# STM32H523 register map
File version: 1.3
CPU: CM33 r0p0, little endian, MPU, FPU, 4 interrupt priority bits
Registers are 32-bit, read-write, reset 0x0 unless marked. A register's access mark holds for its fields unless they carry their own. Offsets are from the block's base; [hi:lo] are bit positions.

## USART1 — USART address block description
Base 0x40013800
Same registers: USART2 0x40004400, USART3 0x40004800, UART4 0x40004C00, UART5 0x40005000, USART6 0x40006400, USART2_S 0x50004400, USART3_S 0x50004800, UART4_S 0x50004C00, UART5_S 0x50005000, USART6_S 0x50006400, USART1_S 0x50013800
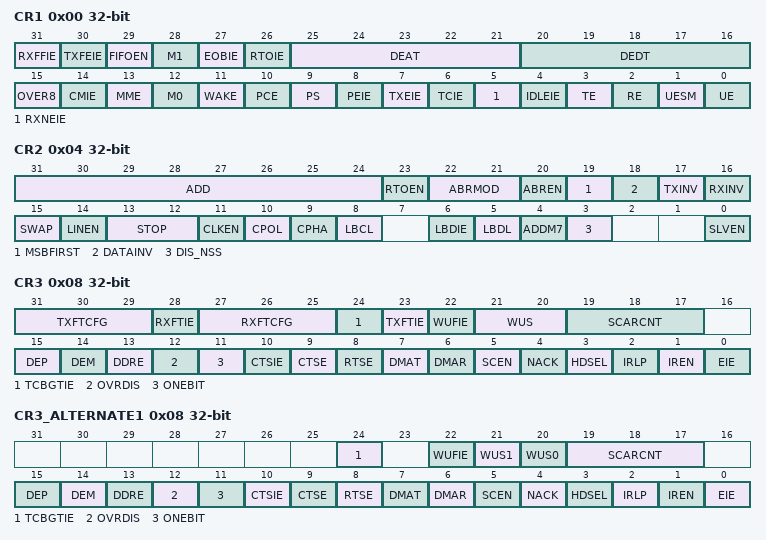
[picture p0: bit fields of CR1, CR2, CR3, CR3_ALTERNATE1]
0x00 CR1 — USART control register 1
  [31] RXFFIE — RXFIFO Full interrupt enable
    0=Disabled (Interrupt inhibited); 1=Enabled (USART interrupt generated when RXFF = 1 in the USART_ISR register)
  [30] TXFEIE — TXFIFO empty interrupt enable
    0=Disabled (Interrupt inhibited); 1=Enabled (USART interrupt generated when TXFE = 1 in the USART_ISR register)
  [29] FIFOEN — FIFO mode enable
    0=Disabled (FIFO mode is disabled); 1=Enabled (FIFO mode is enabled)
  [28] M1 — Word length
    0=M0 (Use M0 to set the data bits); 1=Bit7 (1 start bit, 7 data bits, n stop bits)
  [27] EOBIE — End of block interrupt enable
    0=Disabled (Interrupt is inhibited); 1=Enabled (A USART interrupt is generated when the EOBF flag is set in the ISR register)
  [26] RTOIE — Receiver timeout interrupt enable
    0=Disabled (Interrupt is inhibited); 1=Enabled (An USART interrupt is generated when the RTOF bit is set in the ISR register)
  [25:21] DEAT — Driver Enable assertion time
  [20:16] DEDT — Driver Enable deassertion time
  [15] OVER8 — Oversampling mode
    0=Oversampling16 (Oversampling by 16); 1=Oversampling8 (Oversampling by 8)
  [14] CMIE — Character match interrupt enable
    0=Disabled (Interrupt is disabled); 1=Enabled (Interrupt is generated when the CMF bit is set in the ISR register)
  [13] MME — Mute mode enable
    0=Disabled (Receiver in active mode permanently); 1=Enabled (Receiver can switch between mute mode and active mode)
  [12] M0 — Word length
    0=Bit8 (1 start bit, 8 data bits, n stop bits); 1=Bit9 (1 start bit, 9 data bits, n stop bits)
  [11] WAKE — Receiver wake-up method
    0=Idle line; 1=Address mask
  [10] PCE — Parity control enable
    0=Disabled (Parity control disabled); 1=Enabled (Parity control enabled)
  [9] PS — Parity selection
    0=Even parity; 1=Odd (Odd parity)
  [8] PEIE — PE interrupt enable
    0=Disabled (Interrupt is disabled); 1=Enabled (Interrupt is generated whenever PE=1 in the ISR register)
  [7] TXEIE — TXFIFO not full interrupt enable
    0=Disabled (Interrupt is disabled); 1=Enabled (Interrupt is generated whenever TXE=1 in the ISR register)
  [6] TCIE — Transmission complete interrupt enable
    0=Disabled (Interrupt is disabled); 1=Enabled (Interrupt is generated whenever TC=1 in the ISR register)
  [5] RXNEIE — RXFIFO not empty interrupt enable
    0=Disabled (Interrupt is disabled); 1=Enabled (Interrupt is generated whenever ORE=1 or RXNE=1 in the ISR register)
  [4] IDLEIE — IDLE interrupt enable
    0=Disabled (Interrupt is disabled); 1=Enabled (Interrupt is generated whenever IDLE=1 in the ISR register)
  [3] TE — Transmitter enable
    0=Disabled (Transmitter is disabled); 1=Enabled (Transmitter is enabled)
  [2] RE — Receiver enable
    0=Disabled (Receiver is disabled); 1=Enabled (Receiver is enabled)
  [1] UESM — USART enable in low-power mode
    0=Disabled (USART not able to wake up the MCU from Stop mode); 1=Enabled (USART able to wake up the MCU from Stop mode)
  [0] UE — USART enable
    0=Disabled (UART is disabled); 1=Enabled (UART is enabled)
0x04 CR2 — USART control register 2
  [31:24] ADD — Address of the USART node
  [23] RTOEN — Receiver timeout enable
    0=Disabled (Receiver timeout feature disabled); 1=Enabled (Receiver timeout feature enabled)
  [22:21] ABRMOD — Auto baud rate mode
    0=Start (Measurement of the start bit is used to detect the baud rate); 1=Edge (Falling edge to falling edge measurement); 2=Frame7F (0x7F frame detection); 3=Frame55 (0x55 frame detection)
  [20] ABREN — Auto baud rate enable
    0=Disabled (Auto baud rate detection is disabled); 1=Enabled (Auto baud rate detection is enabled)
  [19] MSBFIRST — Most significant bit first
    0=LSB (data is transmitted/received with data bit 0 first, following the start bit); 1=MSB (data is transmitted/received with MSB (bit 7/8/9) first, following the start bit)
  [18] DATAINV — Binary data inversion
    0=Positive (Logical data from the data register are send/received in positive/direct logic); 1=Negative (Logical data from the data register are send/received in negative/inverse logic)
  [17] TXINV — TX pin active level inversion
    0=Standard (TX pin signal works using the standard logic levels); 1=Inverted (TX pin signal values are inverted)
  [16] RXINV — RX pin active level inversion
    0=Standard (RX pin signal works using the standard logic levels); 1=Inverted (RX pin signal values are inverted)
  [15] SWAP — Swap TX/RX pins
    0=Standard (TX/RX pins are used as defined in standard pinout); 1=Swapped (The TX and RX pins functions are swapped)
  [14] LINEN — LIN mode enable
    0=Disabled (LIN mode disabled); 1=Enabled (LIN mode enabled)
  [13:12] STOP — stop bits
    0=1 stop bit; 1=Stop0p5 (0.5 stop bit); 2=2 stop bit; 3=Stop1p5 (1.5 stop bit)
  [11] CLKEN — Clock enable
    0=Disabled (CK pin disabled); 1=Enabled (CK pin enabled)
  [10] CPOL — Clock polarity
    0=Low (Steady low value on CK pin outside transmission window); 1=High (Steady high value on CK pin outside transmission window)
  [9] CPHA — Clock phase
    0=First (The first clock transition is the first data capture edge); 1=Second (The second clock transition is the first data capture edge)
  [8] LBCL — Last bit clock pulse
    0=NotOutput (The clock pulse of the last data bit is not output to the CK pin); 1=Output (The clock pulse of the last data bit is output to the CK pin)
  [6] LBDIE — LIN break detection interrupt enable
    0=Disabled (Interrupt is inhibited); 1=Enabled (An interrupt is generated whenever LBDF=1 in the ISR register)
  [5] LBDL — LIN break detection length
    0=Bit10 (10-bit break detection); 1=Bit11 (11-bit break detection)
  [4] ADDM7 — 7-bit Address Detection/4-bit Address Detection
    0=Bit4 (4-bit address detection); 1=Bit7 (7-bit address detection)
  [3] DIS_NSS — When the DIS_NSS bit is set, the NSS pin input is ignored.
    0=Disabled (SPI slave selection depends on NSS input pin); 1=Enabled (SPI slave is always selected and NSS input pin is ignored)
  [0] SLVEN — Synchronous slave mode enable
    0=Disabled (Slave mode disabled); 1=Enabled (Slave mode enabled)
0x08 CR3 — USART control register 3
  [31:29] TXFTCFG — TXFIFO threshold configuration
    0=Depth_1_8 (TXFIFO reaches 1/8 of its depth); 1=Depth_1_4 (TXFIFO reaches 1/4 of its depth); 2=Depth_1_2 (TXFIFO reaches 1/2 of its depth); 3=Depth_3_4 (TXFIFO reaches 3/4 of its depth); 4=Depth_7_8 (TXFIFO reaches 7/8 of its depth); 5=Empty (TXFIFO becomes empty)
  [28] RXFTIE — RXFIFO threshold interrupt enable
    0=Disabled (Interrupt inhibited); 1=Enabled (USART interrupt generated when Receive FIFO reaches the threshold programmed in RXFTCFG)
  [27:25] RXFTCFG — Receive FIFO threshold configuration
    0=Depth_1_8 (RXFIFO reaches 1/8 of its depth); 1=Depth_1_4 (RXFIFO reaches 1/4 of its depth); 2=Depth_1_2 (RXFIFO reaches 1/2 of its depth); 3=Depth_3_4 (RXFIFO reaches 3/4 of its depth); 4=Depth_7_8 (RXFIFO reaches 7/8 of its depth); 5=Full (RXFIFO becomes full)
  [24] TCBGTIE — Transmission Complete before guard time, interrupt enable
    0=Disabled (Interrupt inhibited); 1=Enabled (USART interrupt generated whenever TCBGT=1 in the USART_ISR register)
  [23] TXFTIE — TXFIFO threshold interrupt enable
    0=Disabled (Interrupt inhibited); 1=Enabled (USART interrupt generated when Transmit FIFO reaches the threshold programmed in TXFTCFG)
  [22] WUFIE — Wake-up from low-power mode interrupt enable
    0=Disabled (Interrupt is inhibited); 1=Enabled (An USART interrupt is generated whenever WUF=1 in the ISR register)
  [21:20] WUS — Wake-up from low-power mode interrupt flag selection
    0=Address (WUF active on address match); 2=Start (WuF active on Start bit detection); 3=RXNE (WUF active on RXNE)
  [19:17] SCARCNT — Smartcard auto-retry count
  [15] DEP — Driver enable polarity selection
    0=High (DE signal is active high); 1=Low (DE signal is active low)
  [14] DEM — Driver enable mode
    0=Disabled (DE function is disabled); 1=Enabled (The DE signal is output on the RTS pin)
  [13] DDRE — DMA Disable on reception Error
    0=NotDisabled (DMA is not disabled in case of reception error); 1=Disabled (DMA is disabled following a reception error)
  [12] OVRDIS — Overrun Disable
    0=Enabled (Overrun Error Flag, ORE, is set when received data is not read before receiving new data); 1=Disabled (Overrun functionality is disabled. If new data is received while the RXNE flag is still set the ORE flag is not set and the new received data overwrites the previous content of the RDR register)
  [11] ONEBIT — One sample bit method enable
    0=Sample3 (Three sample bit method); 1=Sample1 (One sample bit method)
  [10] CTSIE — CTS interrupt enable
    0=Disabled (Interrupt is inhibited); 1=Enabled (An interrupt is generated whenever CTSIF=1 in the ISR register)
  [9] CTSE — CTS enable
    0=Disabled (CTS hardware flow control disabled); 1=Enabled (CTS mode enabled, data is only transmitted when the CTS input is asserted)
  [8] RTSE — RTS enable
    0=Disabled (RTS hardware flow control disabled); 1=Enabled (RTS output enabled, data is only requested when there is space in the receive buffer)
  [7] DMAT — DMA enable transmitter
    0=Disabled (DMA mode is disabled for transmission); 1=Enabled (DMA mode is enabled for transmission)
  [6] DMAR — DMA enable receiver
    0=Disabled (DMA mode is disabled for reception); 1=Enabled (DMA mode is enabled for reception)
  [5] SCEN — Smartcard mode enable
    0=Disabled (Smartcard Mode disabled); 1=Enabled (Smartcard Mode enabled)
  [4] NACK — Smartcard NACK enable
    0=Disabled (NACK transmission in case of parity error is disabled); 1=Enabled (NACK transmission during parity error is enabled)
  [3] HDSEL — Half-duplex selection
    0=NotSelected (Half duplex mode is not selected); 1=Selected (Half duplex mode is selected)
  [2] IRLP — IrDA low-power
    0=Normal mode; 1=Low-power mode
  [1] IREN — IrDA mode enable
    0=Disabled (IrDA disabled); 1=Enabled (IrDA enabled)
  [0] EIE — Error interrupt enable
    0=Disabled (Interrupt is inhibited); 1=Enabled (An interrupt is generated when FE=1 or ORE=1 or NF=1 in the ISR register)
0x08 CR3_ALTERNATE1 (alternate view of CR3) — USART control register 3
  [24] TCBGTIE — Transmission Complete before guard time, interrupt enable
  [22] WUFIE — Wake-up from low-power mode interrupt enable
  [21] WUS1 — Wake-up from low-power mode interrupt flag selection
  [20] WUS0 — Wake-up from low-power mode interrupt flag selection
  [19:17] SCARCNT — Smartcard auto-retry count
  [15] DEP — Driver enable polarity selection
  [14] DEM — Driver enable mode
  [13] DDRE — DMA Disable on reception Error
  [12] OVRDIS — Overrun Disable
  [11] ONEBIT — One sample bit method enable
  [10] CTSIE — CTS interrupt enable
  [9] CTSE — CTS enable
  [8] RTSE — RTS enable
  [7] DMAT — DMA enable transmitter
  [6] DMAR — DMA enable receiver
  [5] SCEN — Smartcard mode enable
  [4] NACK — Smartcard NACK enable
  [3] HDSEL — Half-duplex selection
  [2] IRLP — IrDA low-power
  [1] IREN — IrDA mode enable
  [0] EIE — Error interrupt enable
0x0C BRR — USART baud rate register
  [15:0] BRR — USART baud rate
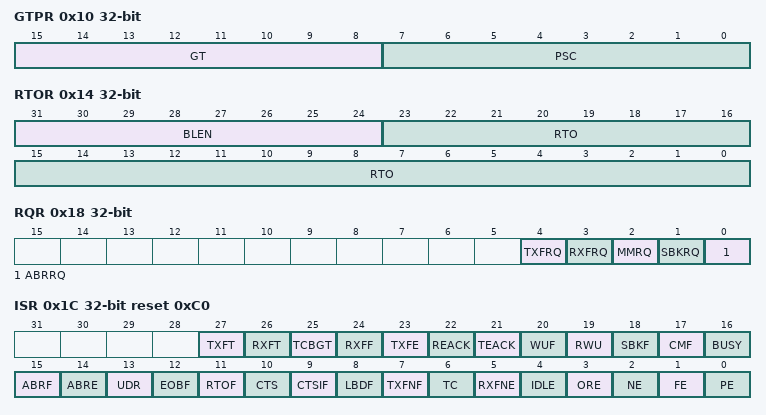
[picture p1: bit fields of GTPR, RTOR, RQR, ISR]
0x10 GTPR — USART guard time and prescaler register
  [15:8] GT — Guard time value
  [7:0] PSC — Prescaler value
0x14 RTOR — USART receiver timeout register
  [31:24] BLEN — Block Length
  [23:0] RTO — Receiver timeout value
0x18 RQR wo — USART request register
  [4] TXFRQ — Transmit data flush request
    1=Discard (Set the TXE flags. This allows to discard the transmit data)
  [3] RXFRQ — Receive data flush request
    1=Discard (clears the RXNE flag. This allows to discard the received data without reading it, and avoid an overrun condition)
  [2] MMRQ — Mute mode request
    1=Mute (Puts the USART in mute mode and sets the RWU flag)
  [1] SBKRQ — Send break request
    1=Break (sets the SBKF flag and request to send a BREAK on the line, as soon as the transmit machine is available)
  [0] ABRRQ — Auto baud rate request
    1=Request (resets the ABRF flag in the USART_ISR and request an automatic baud rate measurement on the next received data frame)
0x1C ISR ro reset 0xC0 (reset mask 0xF00FFFFF) — USART interrupt and status register
  [27] TXFT — TXFIFO threshold flag
    0=NotReached (TXFIFO does not reach the programmed threshold.); 1=Reached (TXFIFO reached the programmed threshold.)
  [26] RXFT — RXFIFO threshold flag
    0=NotReached (Receive FIFO does not reach the programmed threshold.); 1=Reached (Receive FIFO reached the programmed threshold.)
  [25] TCBGT — Transmission complete before guard time flag
    0=NotCompleted (Transmission is not complete or transmission is complete unsuccessfully (i.e. a NACK is received from the card)); 1=Completed (Transmission is complete successfully (before Guard time completion and there is no NACK from the smart card))
  [24] RXFF — RXFIFO Full
    0=NotFull (RXFIFO not full.); 1=Full (RXFIFO Full.)
  [23] TXFE — TXFIFO Empty
    0=NotEmpty (TXFIFO not empty.); 1=Empty (TXFIFO empty.)
  [22] REACK — Receive enable acknowledge flag
  [21] TEACK — Transmit enable acknowledge flag
  [20] WUF — Wake-up from low-power mode flag
  [19] RWU — Receiver wake-up from mute mode
    0=Active (Receiver in Active mode); 1=Mute (Receiver in Mute mode)
  [18] SBKF — Send break flag
    0=No break character transmitted; 1=Break character transmitted
  [17] CMF — Character match flag
    0=NoMatch (No Character match detected); 1=Match (Character match detected)
  [16] BUSY — Busy flag
    0=Idle (USART is idle (no reception)); 1=Busy (Reception on going)
  [15] ABRF — Auto baud rate flag
  [14] ABRE — Auto baud rate error
  [13] UDR — SPI slave underrun error flag
    0=No underrun error; 1=underrun error
  [12] EOBF — End of block flag
    0=NotReached (End of Block not reached); 1=Reached (End of Block (number of characters) reached)
  [11] RTOF — Receiver timeout
    0=NotReached (Timeout value not reached); 1=Reached (Timeout value reached without any data reception)
  [10] CTS — CTS flag
    0=Set (CTS line set); 1=Reset (CTS line reset)
  [9] CTSIF — CTS interrupt flag
    0=NotChanged (No change occurred on the CTS status line); 1=Changed (A change occurred on the CTS status line)
  [8] LBDF — LIN break detection flag
    0=NotDetected (LIN break not detected); 1=Detected (LIN break detected)
  [7] TXFNF — TXFIFO not full
    0=Full (Transmit FIFO is full); 1=NotFull (Transmit FIFO is not full)
  [6] TC — Transmission complete
    0=TxNotComplete (Transmission is not complete); 1=TxComplete (Transmission is complete)
  [5] RXFNE — RXFIFO not empty
    0=NoData (Data is not received); 1=DataReady (Received data is ready to be read)
  [4] IDLE — Idle line detected
    0=No Idle Line is detected; 1=Idle Line is detected
  [3] ORE — Overrun error
    0=No Overrun error; 1=Overrun error is detected
  [2] NE — Noise detection flag
    0=No noise is detected; 1=Noise is detected
  [1] FE — Framing error
    0=NoError (No Framing error is detected); 1=Error (Framing error or break character is detected)
  [0] PE — Parity error
    0=NoError (No parity error); 1=Error (Parity error)
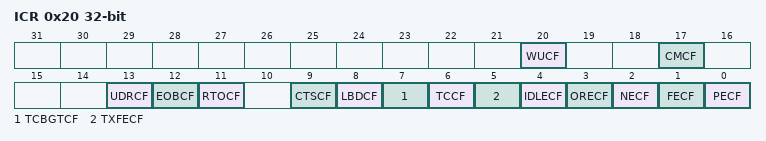
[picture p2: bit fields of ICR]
0x20 ICR wo — USART interrupt flag clear register
  [20] WUCF write-1-clears — Wake-up from low-power mode clear flag
    1=Clears the WUF flag in the ISR register
  [17] CMCF write-1-clears — Character match clear flag
    1=Clears the CMF flag in the ISR register
  [13] UDRCF write-1-clears — SPI slave underrun clear flag
    1=Clear the UDR flag in the ISR register
  [12] EOBCF write-1-clears — End of block clear flag
    1=Clears the EOBF flag in the ISR register
  [11] RTOCF write-1-clears — Receiver timeout clear flag
    1=Clears the RTOF flag in the ISR register
  [9] CTSCF write-1-clears — CTS clear flag
    1=Clears the CTSIF flag in the ISR register
  [8] LBDCF write-1-clears — LIN break detection clear flag
    1=Clears the LBDF flag in the ISR register
  [7] TCBGTCF write-1-clears — Transmission complete before Guard time clear flag
    1=Clear the TCBGT flag in the ISR register
  [6] TCCF write-1-clears — Transmission complete clear flag
    1=Clears the TC flag in the ISR register
  [5] TXFECF write-1-clears — TXFIFO empty clear flag
    1=Clear the TXFE flag in the ISR register
  [4] IDLECF write-1-clears — Idle line detected clear flag
    1=Clears the IDLE flag in the ISR register
  [3] ORECF write-1-clears — Overrun error clear flag
    1=Clears the ORE flag in the ISR register
  [2] NECF write-1-clears — Noise detected clear flag
    1=Clears the NF flag in the ISR register
  [1] FECF write-1-clears — Framing error clear flag
    1=Clears the FE flag in the ISR register
  [0] PECF write-1-clears — Parity error clear flag
    1=Clears the PE flag in the ISR register
0x24 RDR ro — USART receive data register
  [8:0] RDR — Receive data value
0x28 TDR — USART transmit data register
  [8:0] TDR — Transmit data value
0x2C PRESC — USART prescaler register
  [3:0] PRESCALER — Clock prescaler
    0=Div1 (Input clock divided by 1); 1=Div2 (Input clock divided by 2); 2=Div4 (Input clock divided by 4); 3=Div6 (Input clock divided by 6); 4=Div8 (Input clock divided by 8); 5=Div10 (Input clock divided by 10); 6=Div12 (Input clock divided by 12); 7=Div16 (Input clock divided by 16); 8=Div32 (Input clock divided by 32); 9=Div64 (Input clock divided by 64); 10=Div128 (Input clock divided by 128); 11=Div256 (Input clock divided by 256)
